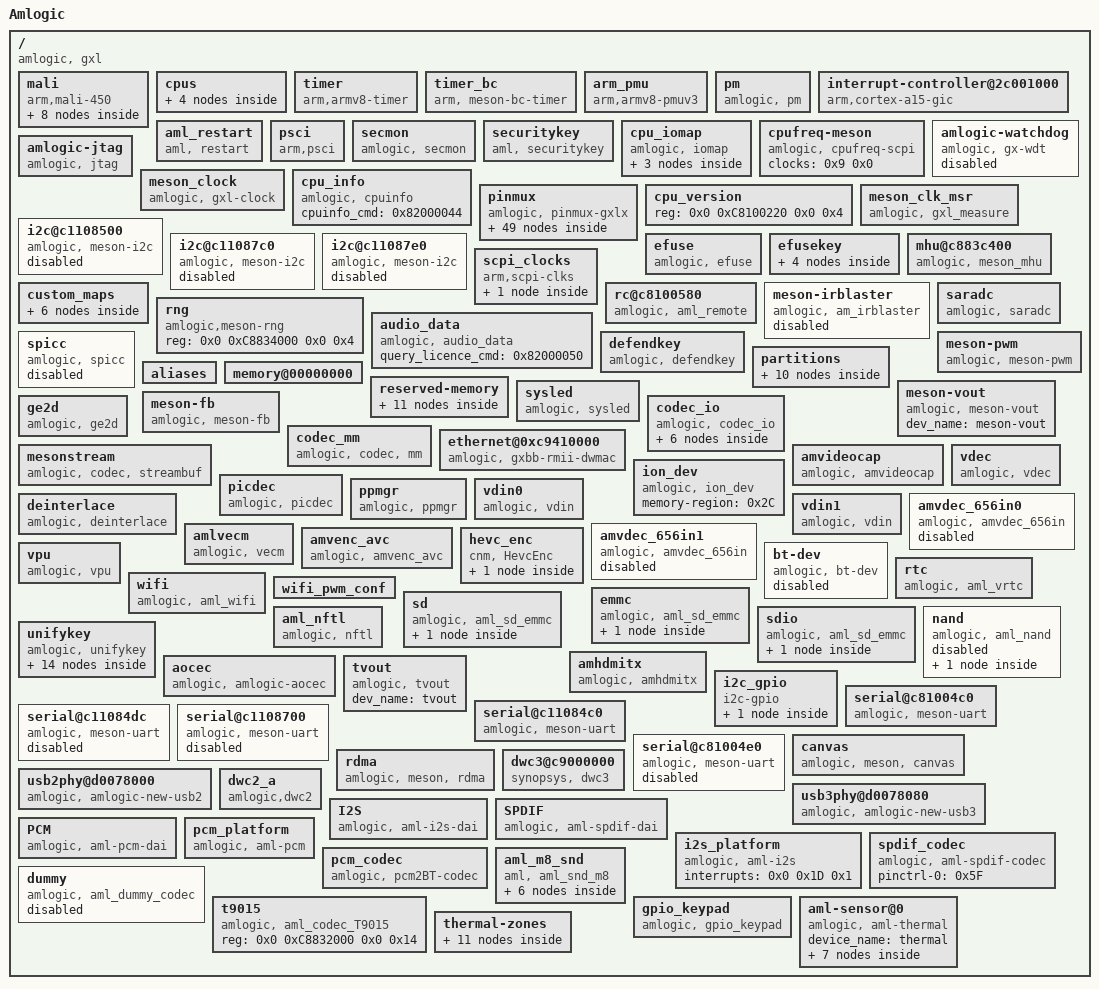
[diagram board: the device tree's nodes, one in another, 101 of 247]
/dts-v1/;
// version: 17
// last_comp_version: 16
// boot_cpuid_phys: 0x0

/ {
    model = "Amlogic";
    compatible = "amlogic, gxl";
    interrupt-parent = <0x1>;
    #address-cells = <0x2>;
    #size-cells = <0x2>;
    mali {
        #cooling-cells = <0x2>;
        compatible = "arm,mali-450";
        interrupt-parent = <0x1>;
        reg = <0x0 0xD00C0000 0x0 0x40000 0x0 0xC1104440 0x0 0x1000 0x0 0xC8100000 0x0 0x1000 0x0 0xC883C000 0x0 0x1000 0x0 0xC1104440 0x0 0x1000>;
        interrupts = <0x0 0xA0 0x4 0x0 0xA1 0x4 0x0 0xA2 0x4 0x0 0xA3 0x4 0x0 0xA4 0x4 0x0 0xA5 0x4 0x0 0xA6 0x4 0x0 0xA7 0x4>;
        interrupt-names = "IRQGP", "IRQGPMMU", "IRQPP", "IRQPMU", "IRQPP0", "IRQPPMMU0", "IRQPP1", "IRQPPMMU1";
        pmu_domain_config = <0x1 0x2 0x4 0x0 0x0 0x0 0x0 0x0 0x0 0x1 0x2 0x0>;
        pmu_switch_delay = <0xFFFF>;
        num_of_pp = <0x2>;
        def_clock = <0x3>;
        sc_mpp = <0x2>;
        tbl = <0x2 0x3 0x4 0x5 0x6 0x6>;
        clocks = <0x7 0x8 0x7 0x9 0x7 0x11 0x7 0x12 0x7 0x1E 0x7 0x15 0x7 0x13 0x7 0x14>;
        clock-names = "fclk_div3", "fclk_div4", "fclk_div5", "fclk_div7", "gp0_pll", "clk_mali", "clk_mali_0", "clk_mali_1";
        control_interval = <0xC8>;
        linux,phandle = <0x74>;
        phandle = <0x74>;
        clk125_cfg {
            clk_freq = <0x7735940>;
            clk_parent = "fclk_div4";
            clkp_freq = <0x1DCD6500>;
            voltage = <0x47E>;
            keep_count = <0x5>;
            threshold = <0x1E 0xFA>;
            linux,phandle = <0x2>;
            phandle = <0x2>;
        };
        clk250_cfg {
            clk_freq = <0xEE6B280>;
            clk_parent = "fclk_div4";
            clkp_freq = <0x1DCD6500>;
            voltage = <0x47E>;
            keep_count = <0x5>;
            threshold = <0x73 0xFA>;
        };
        clk285_cfg {
            clk_freq = <0x10FCC140>;
            clk_parent = "fclk_div7";
            clkp_freq = <0x10FCC140>;
            voltage = <0x47E>;
            keep_count = <0x5>;
            threshold = <0x64 0xFA>;
            linux,phandle = <0x3>;
            phandle = <0x3>;
        };
        clk400_cfg {
            clk_freq = <0x17D78400>;
            clk_parent = "fclk_div5";
            clkp_freq = <0x17D78400>;
            voltage = <0x47E>;
            keep_count = <0x3>;
            threshold = <0xA8 0xFA>;
            linux,phandle = <0x4>;
            phandle = <0x4>;
        };
        clk500_cfg {
            clk_freq = <0x1DCD6500>;
            clk_parent = "fclk_div4";
            clkp_freq = <0x1DCD6500>;
            voltage = <0x47E>;
            keep_count = <0x2>;
            threshold = <0xBE 0xFA>;
            linux,phandle = <0x5>;
            phandle = <0x5>;
        };
        clk666_cfg {
            clk_freq = <0x27B25A80>;
            clk_parent = "fclk_div3";
            clkp_freq = <0x27B25A80>;
            voltage = <0x47E>;
            keep_count = <0x1>;
            threshold = <0xB1 0xFA>;
            linux,phandle = <0x6>;
            phandle = <0x6>;
        };
        clk750_cfg {
            clk_freq = <0x2C588A00>;
            clk_parent = "gp0_pll";
            clkp_freq = <0x2C588A00>;
            voltage = <0x47E>;
            keep_count = <0x1>;
            threshold = <0xD5 0xFF>;
        };
        clk800_cfg {
            clk_freq = <0x2F34F600>;
            clk_parent = "gp0_pll";
            clkp_freq = <0x2F34F600>;
            voltage = <0x47E>;
            keep_count = <0x1>;
            threshold = <0xE6 0xFF>;
        };
    };
    cpus {
        #address-cells = <0x2>;
        #size-cells = <0x0>;
        #cooling-cells = <0x2>;
        linux,phandle = <0x72>;
        phandle = <0x72>;
        cpu@0 {
            device_type = "cpu";
            compatible = "arm,cortex-a53", "arm,armv8";
            reg = <0x0 0x0>;
            enable-method = "psci";
        };
        cpu@1 {
            device_type = "cpu";
            compatible = "arm,cortex-a53", "arm,armv8";
            reg = <0x0 0x1>;
            enable-method = "psci";
        };
        cpu@2 {
            device_type = "cpu";
            compatible = "arm,cortex-a53", "arm,armv8";
            reg = <0x0 0x2>;
            enable-method = "psci";
        };
        cpu@3 {
            device_type = "cpu";
            compatible = "arm,cortex-a53", "arm,armv8";
            reg = <0x0 0x3>;
            enable-method = "psci";
        };
    };
    timer {
        compatible = "arm,armv8-timer";
        interrupts = <0x1 0xD 0xFF01 0x1 0xE 0xFF01 0x1 0xB 0xFF01 0x1 0xA 0xFF01>;
    };
    timer_bc {
        compatible = "arm, meson-bc-timer";
        reg = <0x0 0xC1109990 0x0 0x4 0x0 0xC1109994 0x0 0x4>;
        timer_name = "Meson TimerF";
        clockevent-rating = <0x12C>;
        clockevent-shift = <0x14>;
        clockevent-features = <0x23>;
        interrupts = <0x0 0x3C 0x1>;
        bit_enable = <0x10>;
        bit_mode = <0xC>;
        bit_resolution = <0x0>;
    };
    arm_pmu {
        compatible = "arm,armv8-pmuv3";
        interrupts = <0x0 0x89 0x4 0x0 0x8A 0x4 0x0 0x99 0x4 0x0 0x9A 0x4>;
    };
    pm {
        compatible = "amlogic, pm";
        device_name = "aml_pm";
        gxbaby-suspend;
        reg = <0x0 0xC81000A8 0x0 0x4 0x0 0xC810023C 0x0 0x4>;
    };
    interrupt-controller@2c001000 {
        compatible = "arm,cortex-a15-gic", "arm,cortex-a9-gic";
        #interrupt-cells = <0x3>;
        #address-cells = <0x0>;
        interrupt-controller;
        reg = <0x0 0xC4301000 0x0 0x1000 0x0 0xC4302000 0x0 0x100>;
        interrupts = <0x1 0x9 0xF04>;
        linux,phandle = <0x1>;
        phandle = <0x1>;
    };
    aml_restart {
        compatible = "aml, restart";
        sys_reset = <0x84000009>;
        sys_poweroff = <0x84000008>;
    };
    psci {
        compatible = "arm,psci";
        method = "smc";
        cpu_suspend = <0xC4000001>;
        cpu_off = <0x84000002>;
        cpu_on = <0xC4000003>;
        migrate = <0xC4000005>;
    };
    secmon {
        compatible = "amlogic, secmon";
        memory-region = <0x8>;
        in_base_func = <0x82000020>;
        out_base_func = <0x82000021>;
    };
    securitykey {
        compatible = "aml, securitykey";
        storage_query = <0x82000060>;
        storage_read = <0x82000061>;
        storage_write = <0x82000062>;
        storage_tell = <0x82000063>;
        storage_verify = <0x82000064>;
        storage_status = <0x82000065>;
        storage_list = <0x82000067>;
        storage_remove = <0x82000068>;
        storage_in_func = <0x82000023>;
        storage_out_func = <0x82000024>;
        storage_block_func = <0x82000025>;
        storage_size_func = <0x82000027>;
    };
    cpu_iomap {
        compatible = "amlogic, iomap";
        #address-cells = <0x2>;
        #size-cells = <0x2>;
        ranges;
        io_cbus_base {
            reg = <0x0 0xC1100000 0x0 0x100000>;
        };
        io_apb_base {
            reg = <0x0 0xD0000000 0x0 0x200000>;
        };
        io_aobus_base {
            reg = <0x0 0xC8100000 0x0 0x100000>;
        };
    };
    cpufreq-meson {
        compatible = "amlogic, cpufreq-scpi";
        status = "okay";
        clocks = <0x9 0x0>;
        clock-names = "cpu_clk";
    };
    amlogic-watchdog {
        compatible = "amlogic, gx-wdt";
        status = "disable";
        default_timeout = <0xA>;
        reset_watchdog_method = <0x1>;
        reset_watchdog_time = <0x2>;
        shutdown_timeout = <0xA>;
        firmware_timeout = <0x6>;
        suspend_timeout = <0x6>;
        reg = <0x0 0xC11098D0 0x0 0x10>;
        clocks = <0x7 0x2>;
    };
    amlogic-jtag {
        compatible = "amlogic, jtag";
        status = "okay";
        pinctrl-names = "jtag_apao_pins", "jtag_apee_pins";
        pinctrl-0 = <0xA>;
        pinctrl-1 = <0xB>;
    };
    meson_clock {
        compatible = "amlogic, gxl-clock";
        reg = <0x0 0xC883C000 0x0 0x1000 0x0 0xC8100000 0x0 0x1000>;
        #clock-cells = <0x1>;
        #reset-cells = <0x1>;
        sys_max = <0x5B8D8000>;
        linux,phandle = <0x7>;
        phandle = <0x7>;
    };
    cpu_info {
        compatible = "amlogic, cpuinfo";
        cpuinfo_cmd = <0x82000044>;
    };
    pinmux {
        compatible = "amlogic, pinmux-gxlx";
        dev_name = "pinmux";
        #pinmux-cells = <0x2>;
        #address-cells = <0x2>;
        #size-cells = <0x2>;
        reg = <0x0 0xC1109880 0x0 0x10>;
        ranges;
        banks@c11080b0 {
            reg = <0x0 0xC88344B0 0x0 0x28 0x0 0xC88344E8 0x0 0x14 0x0 0xC8834520 0x0 0x14 0x0 0xC8834430 0x0 0x40>;
            reg-names = "mux", "pull", "pull-enable", "gpio";
            gpio-controller;
            #gpio-cells = <0x2>;
            linux,phandle = <0x28>;
            phandle = <0x28>;
        };
        ao-bank@c1108030 {
            reg = <0x0 0xC8100014 0x0 0x8 0x0 0xC810002C 0x0 0x4 0x0 0xC8100024 0x0 0x8>;
            reg-names = "mux", "pull", "gpio";
            gpio-controller;
            #gpio-cells = <0x2>;
            linux,phandle = <0x6F>;
            phandle = <0x6F>;
        };
        internal_eth_pins {
            amlogic,setmask = <0x4 0x3000000>;
            amlogic,clrmask = <0x3 0x300000>;
            amlogic,pins = "GPIOZ_14", "GPIOZ_15";
        };
        jtag_apao_pin {
            amlogic,clrmask = <0x6 0x7FE0000>;
            amlogic,pins = "GPIOH_6", "GPIOH_7", "GPIOH_8", "GPIOH_9";
            linux,phandle = <0xA>;
            phandle = <0xA>;
        };
        jtag_apee_pin {
            amlogic,clrmask = <0x6 0x3C>;
            amlogic,pins = "CARD_0", "CARD_1", "CARD_2", "CARD_3";
            linux,phandle = <0xB>;
            phandle = <0xB>;
        };
        remote_pin {
            amlogic,setmask = <0x10 0x1>;
            amlogic,clrmask = <0x10 0x200000>;
            amlogic,pins = "GPIOAO_7";
            linux,phandle = <0x15>;
            phandle = <0x15>;
        };
        irblaster_pin {
            amlogic,setmask = <0x10 0x200000>;
            amlogic,clrmask = <0x10 0x1>;
            amlogic,pins = "GPIOAO_7";
            linux,phandle = <0x17>;
            phandle = <0x17>;
        };
        ao_uart {
            amlogic,setmask = <0x10 0x1800>;
            amlogic,pins = "GPIOAO_0", "GPIOAO_1";
        };
        ao_b_uart {
            amlogic,setmask = <0x10 0x1800000>;
            amlogic,pins = "GPIOAO_4", "GPIOAO_5";
            linux,phandle = <0x5B>;
            phandle = <0x5B>;
        };
        a_uart {
            amlogic,setmask = <0x5 0xF0000>;
            amlogic,clrmask = <0x5 0x3C0>;
            amlogic,pins = "GPIOX_12", "GPIOX_13", "GPIOX_14", "GPIOX_15";
            linux,phandle = <0x58>;
            phandle = <0x58>;
        };
        b_uart {
            amlogic,setmask = <0x2 0x18000>;
            amlogic,pins = "GPIODV_24", "GPIODV_25";
            linux,phandle = <0x59>;
            phandle = <0x59>;
        };
        c_uart {
            amlogic,setmask = <0x5 0x3000>;
            amlogic,pins = "GPIOX_8", "GPIOX_9";
            linux,phandle = <0x5A>;
            phandle = <0x5A>;
        };
        wifi_32k_pins {
            amlogic,setmask = <0x5 0x8000>;
            amlogic,pins = "GPIOX_16";
            linux,phandle = <0x31>;
            phandle = <0x31>;
        };
        sd_clk_cmd_pins {
            amlogic,setmask = <0x6 0xC 0x10 0x1800>;
            amlogic,pins = "CARD_2", "CARD_3";
            amlogic,enable-output = <0x1>;
            amlogic,pullup = <0x1>;
            amlogic,pullupen = <0x1>;
            linux,phandle = <0x36>;
            phandle = <0x36>;
        };
        sd_all_pins {
            amlogic,setmask = <0x6 0x3F 0x10 0x1800>;
            amlogic,clrmask = <0x6 0xFC0>;
            amlogic,pins = "CARD_0", "CARD_1", "CARD_2", "CARD_3", "CARD_4", "CARD_5";
            amlogic,enable-output = <0x1>;
            amlogic,pullup = <0x1>;
            amlogic,pullupen = <0x1>;
            linux,phandle = <0x37>;
            phandle = <0x37>;
        };
        sd_clear_all_pin {
            amlogic,setmask = <0x10 0x1800>;
            amlogic,clrmask = <0x6 0x3F 0x6 0xFC0>;
            amlogic,pins = "GPIOAO_0", "GPIOAO_1";
            amlogic,enable-output = <0x1>;
            amlogic,pullup = <0x1>;
            amlogic,pullupen = <0x1>;
            linux,phandle = <0x3F>;
            phandle = <0x3F>;
        };
        sd_1bit_pins {
            amlogic,setmask = <0x6 0x1C 0x10 0x1800>;
            amlogic,clrmask = <0x6 0xCC3>;
            amlogic,pins = "CARD_1", "CARD_2", "CARD_3";
            amlogic,enable-output = <0x1>;
            amlogic,pullup = <0x1>;
            amlogic,pullupen = <0x1>;
            linux,phandle = <0x38>;
            phandle = <0x38>;
        };
        sd_clk_cmd_uart_pins {
            amlogic,setmask = <0x6 0x30C>;
            amlogic,clrmask = <0x6 0xCC3 0x10 0x1800>;
            amlogic,pins = "CARD_2", "CARD_3";
            amlogic,enable-output = <0x1>;
            amlogic,pullup = <0x1>;
            amlogic,pullupen = <0x1>;
            linux,phandle = <0x39>;
            phandle = <0x39>;
        };
        sd_1bit_uart_pins {
            amlogic,setmask = <0x6 0x31C>;
            amlogic,clrmask = <0x6 0xCC3 0x10 0x1800>;
            amlogic,pins = "CARD_1", "CARD_2", "CARD_3";
            amlogic,enable-output = <0x1>;
            amlogic,pullup = <0x1>;
            amlogic,pullupen = <0x1>;
            linux,phandle = <0x3A>;
            phandle = <0x3A>;
        };
        sd_to_ao_uart_pins {
            amlogic,setmask = <0x10 0x1800>;
            amlogic,clrmask = <0x6 0x300>;
            amlogic,pins = "GPIOAO_0", "GPIOAO_1";
            amlogic,enable-output = <0x1>;
            amlogic,pullup = <0x1>;
            amlogic,pullupen = <0x1>;
            linux,phandle = <0x3B>;
            phandle = <0x3B>;
        };
        ao_to_sd_uart_pins {
            amlogic,setmask = <0x6 0x300>;
            amlogic,clrmask = <0x10 0x1800 0x6 0xCC3>;
            amlogic,pins = "CARD_4", "CARD_5";
            amlogic,enable-output = <0x1>;
            amlogic,pullup = <0x1>;
            amlogic,pullupen = <0x1>;
            linux,phandle = <0x3C>;
            phandle = <0x3C>;
        };
        ao_to_sd_jtag_pins {
            amlogic,setmask = <0x6 0x300>;
            amlogic,clrmask = <0x6 0xCFF 0x10 0x1800>;
            amlogic,pins = "CARD_4", "CARD_5";
            amlogic,enable-output = <0x1>;
            amlogic,pullup = <0x1>;
            amlogic,pullupen = <0x1>;
            linux,phandle = <0x3D>;
            phandle = <0x3D>;
        };
        sd_to_ao_jtag_pins {
            amlogic,setmask = <0x10 0x1800>;
            amlogic,clrmask = <0x6 0xFC0>;
            amlogic,pins = "GPIOAO_0", "GPIOAO_1";
            amlogic,enable-output = <0x1>;
            amlogic,pullup = <0x1>;
            amlogic,pullupen = <0x1>;
            linux,phandle = <0x3E>;
            phandle = <0x3E>;
        };
        emmc_conf_pull_up {
            amlogic,pins = "BOOT_0", "BOOT_1", "BOOT_2", "BOOT_3", "BOOT_4", "BOOT_5", "BOOT_6", "BOOT_7", "BOOT_8", "BOOT_10";
            amlogic,pullup = <0x1>;
            amlogic,pullupen = <0x1>;
            linux,phandle = <0x33>;
            phandle = <0x33>;
        };
        emmc_conf_pull_done {
            amlogic,pins = "BOOT_15";
            amlogic,pullup = <0x0>;
            amlogic,pullupen = <0x1>;
            linux,phandle = <0x34>;
            phandle = <0x34>;
        };
        emmc_clk_cmd_pins {
            amlogic,setmask = <0x7 0x60000000>;
            amlogic,clrmask = <0x7 0xE0>;
            amlogic,pins = "BOOT_8", "BOOT_10";
            amlogic,enable-output = <0x1>;
            amlogic,pullup = <0x1>;
            amlogic,pullupen = <0x1>;
            linux,phandle = <0x32>;
            phandle = <0x32>;
        };
        emmc_all_pins {
            amlogic,setmask = <0x7 0xF0000000>;
            amlogic,clrmask = <0x7 0xE0>;
            amlogic,pins = "BOOT_0", "BOOT_1", "BOOT_2", "BOOT_3", "BOOT_4", "BOOT_5", "BOOT_6", "BOOT_7", "BOOT_8", "BOOT_10", "BOOT_15";
            amlogic,enable-output = <0x1>;
            linux,phandle = <0x35>;
            phandle = <0x35>;
        };
        sdio_clk_cmd_pins {
            amlogic,setmask = <0x5 0xC000000>;
            amlogic,pins = "GPIOX_4", "GPIOX_5";
            amlogic,enable-output = <0x1>;
            amlogic,pullup = <0x1>;
            amlogic,pullupen = <0x1>;
            linux,phandle = <0x40>;
            phandle = <0x40>;
        };
        sdio_all_pins {
            amlogic,setmask = <0x5 0xFC000000>;
            amlogic,pins = "GPIOX_0", "GPIOX_1", "GPIOX_2", "GPIOX_3", "GPIOX_4", "GPIOX_5";
            amlogic,enable-output = <0x1>;
            amlogic,pullup = <0x1>;
            amlogic,pullupen = <0x1>;
            linux,phandle = <0x41>;
            phandle = <0x41>;
        };
        conf_nand_pulldown {
            amlogic,pins = "BOOT_0", "BOOT_1", "BOOT_2", "BOOT_3", "BOOT_4", "BOOT_5", "BOOT_6", "BOOT_7", "BOOT_15";
            amlogic,pullup = <0x0>;
            amlogic,pullupen = <0x1>;
            linux,phandle = <0x42>;
            phandle = <0x42>;
        };
        conf_nand_pullup {
            amlogic,pins = "BOOT_8", "BOOT_10";
            amlogic,pullup = <0x1>;
            amlogic,pullupen = <0x1>;
            linux,phandle = <0x43>;
            phandle = <0x43>;
        };
        all_nand_pins {
            amlogic,setmask = <0x7 0x800000FF>;
            amlogic,clrmask = <0x7 0x70FFBC00>;
            amlogic,pins = "BOOT_0", "BOOT_1", "BOOT_2", "BOOT_3", "BOOT_4", "BOOT_5", "BOOT_6", "BOOT_7", "BOOT_8", "BOOT_9", "BOOT_10", "BOOT_11", "BOOT_12", "BOOT_13", "BOOT_14", "BOOT_15";
            amlogic,enable-output = <0x1>;
            linux,phandle = <0x44>;
            phandle = <0x44>;
        };
        nand_cs {
            amlogic,setmask = <0x7 0xC0>;
            amlogic,clrmask = <0x7 0x40040000>;
            amlogic,pins = "BOOT_8", "BOOT_9";
            linux,phandle = <0x45>;
            phandle = <0x45>;
        };
        hdmitx_hpd {
            amlogic,setmask = <0x6 0x80000000>;
            amlogic,pins = "GPIOH_0";
            linux,phandle = <0x55>;
            phandle = <0x55>;
        };
        hdmitx_ddc {
            amlogic,setmask = <0x6 0x30000000>;
            amlogic,pins = "GPIOH_1", "GPIOH_2";
            linux,phandle = <0x56>;
            phandle = <0x56>;
        };
        hdmitx_aocec {
            amlogic,setmask = <0x10 0x8000>;
            amlogic,clrmask = <0x10 0x24000 0x11 0x1>;
            amlogic,pins = "GPIOAO_8";
            linux,phandle = <0x57>;
            phandle = <0x57>;
        };
        hdmitx_eecec {
            amlogic,setmask = <0x10 0x4000>;
            amlogic,clrmask = <0x10 0x28000 0x11 0x1>;
            amlogic,pins = "GPIOAO_8";
        };
        a_i2c {
            amlogic,setmask = <0x1 0xC000>;
            amlogic,clrmask = <0x3 0x18 0x2 0x18000 0x2 0xC0 0x1 0x600000>;
            amlogic,pins = "GPIODV_24", "GPIODV_25";
            linux,phandle = <0xC>;
            phandle = <0xC>;
        };
        b_i2c {
            amlogic,setmask = <0x1 0x3000>;
            amlogic,clrmask = <0x2 0x6000 0x1 0x1C0000>;
            amlogic,pins = "GPIODV_26", "GPIODV_27";
            linux,phandle = <0xD>;
            phandle = <0xD>;
        };
        c_i2c {
            amlogic,setmask = <0x1 0xC00>;
            amlogic,clrmask = <0x2 0x1800 0x1 0x200 0x2 0x20>;
            amlogic,pins = "GPIODV_28", "GPIODV_29";
            linux,phandle = <0xE>;
            phandle = <0xE>;
        };
        spicc_pins_z11z12z13 {
            amlogic,setmask = <0x4 0x1C>;
            amlogic,clrmask = <0x3 0x800 0x4 0x1C00>;
            amlogic,pins = "GPIOZ_11", "GPIOZ_12", "GPIOZ_13";
        };
        spicc_pulldown_z11z12z13 {
            amlogic,pins = "GPIOZ_11", "GPIOZ_12", "GPIOZ_13";
            amlogic,pullup = <0x0>;
            amlogic,pullupen = <0x1>;
        };
        spicc_pullup_z11z12z13 {
            amlogic,pins = "GPIOZ_11", "GPIOZ_12", "GPIOZ_13";
            amlogic,pullup = <0x1>;
            amlogic,pullupen = <0x1>;
        };
        spicc_pins_x8x9x11 {
            amlogic,setmask = <0x5 0xD>;
            amlogic,clrmask = <0x5 0xD03430 0x6 0xD>;
            amlogic,pins = "GPIOX_8", "GPIOX_9", "GPIOX_11";
        };
        spicc_pulldown_x8x9x11 {
            amlogic,pins = "GPIOX_8", "GPIOX_9", "GPIOX_11";
            amlogic,pullup = <0x0>;
            amlogic,pullupen = <0x1>;
        };
        spicc_pullup_x8x9x11 {
            amlogic,pins = "GPIOX_8", "GPIOX_9", "GPIOX_11";
            amlogic,pullup = <0x1>;
            amlogic,pullupen = <0x1>;
        };
        audio_pin {
            amlogic,setmask = <0x6 0x7800000>;
            amlogic,clrmask = <0x6 0x7E0000>;
            amlogic,pins = "GPIOH_6", "GPIOH_7", "GPIOH_8", "GPIOH_9";
            linux,phandle = <0x60>;
            phandle = <0x60>;
        };
        audio_pin1 {
            amlogic,setmask = <0x6 0x10000000>;
            amlogic,clrmask = <0x6 0x8000000>;
            amlogic,pins = "GPIOH_4";
            linux,phandle = <0x5F>;
            phandle = <0x5F>;
        };
        audio_btpcm_pins {
            amlogic,setmask = <0x5 0xF00000>;
            amlogic,clrmask = <0x5 0x3C33>;
            amlogic,pins = "GPIOX_8", "GPIOX_9", "GPIOX_10", "GPIOX_11";
            linux,phandle = <0x5E>;
            phandle = <0x5E>;
        };
    };
    cpu_version {
        reg = <0x0 0xC8100220 0x0 0x4>;
    };
    meson_clk_msr {
        compatible = "amlogic, gxl_measure";
        reg = <0x0 0xC110875C 0x0 0x4 0x0 0xC1108764 0x0 0x4>;
    };
    i2c@c1108500 {
        compatible = "amlogic, meson-i2c";
        dev_name = "i2c-A";
        status = "disabled";
        reg = <0x0 0xC1108500 0x0 0x20>;
        device_id = <0x1>;
        pinctrl-names = "default";
        pinctrl-0 = <0xC>;
        #address-cells = <0x1>;
        #size-cells = <0x0>;
        use_pio = <0x0>;
        master_i2c_speed = <0x493E0>;
        clocks = <0x7 0xA>;
        clock-names = "clk_i2c";
        resets = <0x7 0x9>;
    };
    i2c@c11087c0 {
        compatible = "amlogic, meson-i2c";
        dev_name = "i2c-B";
        status = "disabled";
        reg = <0x0 0xC11087C0 0x0 0x20>;
        device_id = <0x2>;
        pinctrl-names = "default";
        pinctrl-0 = <0xD>;
        #address-cells = <0x1>;
        #size-cells = <0x0>;
        use_pio = <0x0>;
        master_i2c_speed = <0x493E0>;
        clocks = <0x7 0xA>;
        clock-names = "clk_i2c";
        resets = <0x7 0x9>;
    };
    i2c@c11087e0 {
        compatible = "amlogic, meson-i2c";
        dev_name = "i2c-C";
        status = "disabled";
        reg = <0x0 0xC11087E0 0x0 0x20>;
        device_id = <0x3>;
        pinctrl-names = "default";
        pinctrl-0 = <0xE>;
        #address-cells = <0x1>;
        #size-cells = <0x0>;
        use_pio = <0x0>;
        master_i2c_speed = <0x493E0>;
        clocks = <0x7 0xA>;
        clock-names = "clk_i2c";
        resets = <0x7 0x9>;
    };
    efuse {
        compatible = "amlogic, efuse";
        read_cmd = <0x82000030>;
        write_cmd = <0x82000031>;
        get_max_cmd = <0x82000033>;
        key = <0xF>;
        resets = <0x7 0x3E>;
        reset-names = "efuse_clk";
        status = "okay";
    };
    efusekey {
        keynum = <0x4>;
        key0 = <0x10>;
        key1 = <0x11>;
        key2 = <0x12>;
        key3 = <0x13>;
        linux,phandle = <0xF>;
        phandle = <0xF>;
        key0 {
            keyname = "mac";
            offset = <0x0>;
            size = <0x6>;
            linux,phandle = <0x10>;
            phandle = <0x10>;
        };
        key1 {
            keyname = "mac_bt";
            offset = <0x6>;
            size = <0x6>;
            linux,phandle = <0x11>;
            phandle = <0x11>;
        };
        key2 {
            keyname = "mac_wifi";
            offset = <0xC>;
            size = <0x6>;
            linux,phandle = <0x12>;
            phandle = <0x12>;
        };
        key3 {
            keyname = "usid";
            offset = <0x12>;
            size = <0x10>;
            linux,phandle = <0x13>;
            phandle = <0x13>;
        };
    };
    mhu@c883c400 {
        compatible = "amlogic, meson_mhu";
        reg = <0x0 0xC883C400 0x0 0x4C 0x0 0xC8013000 0x0 0x800>;
        interrupts = <0x0 0xD1 0x8 0x0 0xD2 0x8>;
        #mbox-cells = <0x1>;
        mbox-names = "cpu_to_scp_low", "cpu_to_scp_high";
        mboxes = <0x14 0x0 0x14 0x1>;
        linux,phandle = <0x14>;
        phandle = <0x14>;
    };
    scpi_clocks {
        compatible = "arm,scpi-clks";
        scpi_clocks@0 {
            compatible = "arm,scpi-clk-indexed";
            #clock-cells = <0x1>;
            clock-indices = <0x0>;
            clock-output-names = "vcpu";
            linux,phandle = <0x9>;
            phandle = <0x9>;
        };
    };
    rc@c8100580 {
        compatible = "amlogic, aml_remote";
        dev_name = "meson-remote";
        reg = <0x0 0xC8100580 0x0 0x44 0x0 0xC8100480 0x0 0x20>;
        status = "okay";
        protocol = <0x1>;
        interrupts = <0x0 0xC4 0x1>;
        pinctrl-names = "default";
        pinctrl-0 = <0x15>;
        map = <0x16>;
        max_frame_time = <0xC8>;
    };
    meson-irblaster {
        compatible = "amlogic, am_irblaster";
        dev_name = "meson-irblaster";
        status = "disabled";
        pinctrl-names = "default";
        pinctrl-0 = <0x17>;
    };
    custom_maps {
        mapnum = <0x6>;
        map0 = <0x18>;
        map1 = <0x19>;
        map2 = <0x1A>;
        map3 = <0x1B>;
        map4 = <0x1C>;
        map5 = <0x1D>;
        linux,phandle = <0x16>;
        phandle = <0x16>;
        map_0 {
            mapname = "cyxtech-remote-a95x";
            customcode = <0xDF00>;
            release_delay = <0x50>;
            size = <0x1B>;
            keymap = <0xC000B 0x540002 0x160003 0x150004 0x500005 0x120006 0x110007 0x4C0008 0xE0009 0xD000A 0x10000E 0x1A0067 0x48006C 0x470069 0x7006A 0x60061 0x4B007A 0x4F007B 0x1C0074 0x420066 0xA009E 0x18008B 0x5D0073 0x5C0072 0x410046 0x10186 0x5F018A>;
            linux,phandle = <0x18>;
            phandle = <0x18>;
        };
        map_1 {
            mapname = "cyxtech-remote-cs918";
            customcode = <0x4040>;
            release_delay = <0x50>;
            size = <0x1D>;
            keymap = <0xB 0x10002 0x20003 0x30004 0x40005 0x50006 0x60007 0x70008 0x80009 0x9000A 0xC000E 0xB0067 0xE006C 0x100069 0x11006A 0xD0061 0x1E007A 0x1F007B 0x4D0074 0x1A0066 0x42009E 0x45008B 0x150073 0x1C0072 0x430071 0x570046 0x5B018B 0x540188 0x530189>;
            linux,phandle = <0x19>;
            phandle = <0x19>;
        };
        map_2 {
            mapname = "cyxtech-remote-8200";
            customcode = <0xFE01>;
            release_delay = <0x50>;
            size = <0x1B>;
            keymap = <0x1000B 0x4E0002 0xD0003 0xC0004 0x4A0005 0x90006 0x80007 0x460008 0x50009 0x4000A 0x42000E 0x160067 0x1A006C 0x510069 0x50006A 0x130061 0x4B007A 0x4F007B 0x400074 0x110066 0x19009E 0x8B 0x180073 0x100072 0x410046 0xF0186 0x43018A>;
            linux,phandle = <0x1A>;
            phandle = <0x1A>;
        };
        map_3 {
            mapname = "cyxtech-remote-test";
            customcode = <0xDF20>;
            release_delay = <0x50>;
            size = <0xC>;
            keymap = <0x410000 0x500000 0x420000 0x1A0000 0x1B0000 0x4F0000 0x430000 0x140000 0x4D0000 0x5A0190 0x560191 0x510192>;
            linux,phandle = <0x1B>;
            phandle = <0x1B>;
        };
        map_4 {
            mapname = "cyxtech-remote-test2";
            customcode = <0xFF00>;
            release_delay = <0x50>;
            size = <0x9>;
            keymap = <0x470190 0x460191 0x450192 0x4A0000 0x4B0000 0x490000 0x4E0000 0x4F0000 0x4D0000>;
            linux,phandle = <0x1C>;
            phandle = <0x1C>;
        };
        map_5 {
            mapname = "remote_mouse_r2a";
            customcode = <0x7F80>;
            release_delay = <0x50>;
            size = <0xC>;
            keymap = <0x810074 0x890072 0x870073 0x730066 0x83008B 0x380067 0x40006C 0x370069 0x39006A 0x130061 0x27009E 0x480184>;
            linux,phandle = <0x1D>;
            phandle = <0x1D>;
        };
    };
    rng {
        compatible = "amlogic,meson-rng";
        reg = <0x0 0xC8834000 0x0 0x4>;
    };
    audio_data {
        compatible = "amlogic, audio_data";
        query_licence_cmd = <0x82000050>;
        status = "okay";
    };
    saradc {
        compatible = "amlogic, saradc";
        status = "okay";
        interrupts = <0x0 0x9 0x1>;
        interrupt-names = "saradc_int";
        clocks = <0x7 0x2>;
        clock-names = "saradc_clk";
        resets = <0x7 0x56>;
        reg = <0x0 0xC1108680 0x0 0x30 0x0 0xC883C3D8 0x0 0x8>;
    };
    defendkey {
        compatible = "amlogic, defendkey";
        reg = <0x0 0xC8834500 0x0 0x4>;
        mem_size = <0x0 0x100000>;
        status = "okay";
    };
    spicc {
        compatible = "amlogic, spicc";
        status = "disabled";
        reg = <0x0 0xC1108D80 0x0 0x28>;
        resets = <0x7 0x8>;
        clocks = <0x7 0xA>;
        clock-names = "spicc_clk";
        interrupts = <0x0 0x51 0x1>;
        device_id = <0x0>;
    };
    meson-pwm {
        compatible = "amlogic, meson-pwm";
        status = "okay";
        #pwm-cells = <0x2>;
        pwm-outputs = <0x0 0x1 0x2 0x3 0x4 0x5 0x6 0x7 0x8 0x9 0xA 0xB 0xC 0xD 0xE 0xF>;
        reg = <0x0 0xC1108550 0x0 0x1C 0x0 0xC1108640 0x0 0x1C 0x0 0xC11086C0 0x0 0x1C 0x0 0xC8100550 0x0 0x1C>;
        clocks = <0x7 0x2 0x7 0x5 0x7 0x9 0x7 0x8>;
        clock-names = "xtal", "vid_pll_clk", "fclk_div4", "fclk_div3";
        clock-select = <0x0 0x0 0x0 0x0 0x0 0x0 0x0 0x0>;
    };
    partitions {
        parts = <0xA>;
        part-0 = <0x1E>;
        part-1 = <0x1F>;
        part-2 = <0x20>;
        part-3 = <0x21>;
        part-4 = <0x22>;
        part-5 = <0x23>;
        part-6 = <0x24>;
        part-7 = <0x25>;
        part-8 = <0x26>;
        part-9 = <0x27>;
        logo {
            pname = "logo";
            size = <0x0 0x2000000>;
            mask = <0x1>;
            linux,phandle = <0x1E>;
            phandle = <0x1E>;
        };
        recovery {
            pname = "recovery";
            size = <0x0 0x2000000>;
            mask = <0x1>;
            linux,phandle = <0x1F>;
            phandle = <0x1F>;
        };
        cri_data {
            pname = "cri_data";
            size = <0x0 0x800000>;
            mask = <0x1>;
            linux,phandle = <0x20>;
            phandle = <0x20>;
        };
        tee {
            pname = "tee";
            size = <0x0 0x800000>;
            mask = <0x1>;
            linux,phandle = <0x21>;
            phandle = <0x21>;
        };
        param {
            pname = "param";
            size = <0x0 0x2000000>;
            mask = <0x1>;
            linux,phandle = <0x22>;
            phandle = <0x22>;
        };
        misc {
            pname = "misc";
            size = <0x0 0x2000000>;
            mask = <0x1>;
            linux,phandle = <0x23>;
            phandle = <0x23>;
        };
        boot {
            pname = "boot";
            size = <0x0 0x2000000>;
            mask = <0x1>;
            linux,phandle = <0x24>;
            phandle = <0x24>;
        };
        system {
            pname = "system";
            size = <0x0 0x80000000>;
            mask = <0x1>;
            linux,phandle = <0x25>;
            phandle = <0x25>;
        };
        cache {
            pname = "cache";
            size = <0x0 0x20000000>;
            mask = <0x2>;
            linux,phandle = <0x26>;
            phandle = <0x26>;
        };
        data {
            pname = "data";
            size = <0xFFFFFFFF 0xFFFFFFFF>;
            mask = <0x4>;
            linux,phandle = <0x27>;
            phandle = <0x27>;
        };
    };
    aliases {
        serial0 = "/serial@c81004c0";
        serial1 = "/serial@c11084c0";
        serial2 = "/serial@c11084dc";
        serial3 = "/serial@c1108700";
        serial4 = "/serial@c81004e0";
    };
    memory@00000000 {
        device_type = "memory";
        linux,usable-memory = <0x0 0x100000 0x0 0x3FF00000>;
    };
    reserved-memory {
        #address-cells = <0x2>;
        #size-cells = <0x2>;
        ranges;
        linux,secmon {
            compatible = "amlogic, aml_secmon_memory";
            reg = <0x0 0x5000000 0x0 0x300000>;
            no-map;
            linux,phandle = <0x8>;
            phandle = <0x8>;
        };
        linux,secos {
            status = "disable";
            compatible = "amlogic, aml_secos_memory";
            reg = <0x0 0x5300000 0x0 0x2000000>;
            no-map;
        };
        aml_pstore {
            compatible = "amlogic, pstore";
            reg = <0x0 0x7300000 0x0 0x100000>;
            no-map;
        };
        linux,meson-fb {
            compatible = "amlogic, fb-memory";
            reg = <0x0 0x3F000000 0x0 0x1000000>;
            no-map;
            linux,phandle = <0x29>;
            phandle = <0x29>;
        };
        linux,di_cma {
            compatible = "shared-dma-pool";
            reusable;
            size = <0x0 0x2400000>;
            alignment = <0x0 0x400000>;
            linux,phandle = <0x2F>;
            phandle = <0x2F>;
        };
        linux,ion-dev {
            compatible = "amlogic, idev-mem";
            size = <0x0 0x2000000>;
            linux,phandle = <0x2C>;
            phandle = <0x2C>;
        };
        linux,vdin1_cma {
            compatible = "shared-dma-pool";
            reusable;
            size = <0x0 0x1000000>;
            alignment = <0x0 0x400000>;
            linux,phandle = <0x30>;
            phandle = <0x30>;
        };
        linux,ppmgr {
            compatible = "amlogic, ppmgr_memory";
            size = <0x0 0x0>;
            multi-use;
            linux,phandle = <0x2E>;
            phandle = <0x2E>;
        };
        linux,codec_mm_cma {
            compatible = "shared-dma-pool";
            reusable;
            size = <0x0 0xBC00000>;
            alignment = <0x0 0x400000>;
            linux,contiguous-region;
            linux,phandle = <0x2A>;
            phandle = <0x2A>;
        };
        linux,picdec {
            compatible = "shared-dma-pool";
            reusable;
            size = <0x0 0x0>;
            alignment = <0x0 0x0>;
            linux,contiguous-region;
            linux,phandle = <0x2D>;
            phandle = <0x2D>;
        };
        linux,codec_mm_reserved {
            compatible = "amlogic, codec-mm-reserved";
            size = <0x0 0x4100000>;
            alignment = <0x0 0x100000>;
            linux,phandle = <0x2B>;
            phandle = <0x2B>;
        };
    };
    sysled {
        compatible = "amlogic, sysled";
        dev_name = "sysled";
        status = "okay";
        led_gpio = <0x28 0x4C 0x0>;
        led_active_low = <0x1>;
    };
    meson-vout {
        compatible = "amlogic, meson-vout";
        dev_name = "meson-vout";
        status = "okay";
    };
    meson-fb {
        compatible = "amlogic, meson-fb";
        memory-region = <0x29>;
        dev_name = "meson-fb";
        status = "okay";
        interrupts = <0x0 0x3 0x1 0x0 0x59 0x1>;
        interrupt-names = "viu-vsync", "rdma";
        mem_size = <0xB00000 0x100000>;
        display_mode_default = "720p60hz";
        scale_mode = <0x1>;
        display_size_default = <0x500 0x2D0 0x500 0x870 0x20>;
        pxp_mode = <0x1>;
        logo_addr = "0x3f000000";
    };
    ge2d {
        compatible = "amlogic, ge2d";
        dev_name = "ge2d";
        status = "okay";
        interrupts = <0x0 0x96 0x1>;
        interrupt-names = "ge2d";
        clocks = <0x7 0x17 0x7 0x19>;
        clock-names = "clk_vapb_0", "clk_ge2d";
        resets = <0x7 0x34>;
        reset-names = "ge2d";
    };
    codec_io {
        compatible = "amlogic, codec_io";
        #address-cells = <0x2>;
        #size-cells = <0x2>;
        ranges;
        io_cbus_base {
            reg = <0x0 0xC1100000 0x0 0x100000>;
        };
        io_dos_base {
            reg = <0x0 0xC8820000 0x0 0x10000>;
        };
        io_hiubus_base {
            reg = <0x0 0xC883C000 0x0 0x2000>;
        };
        io_aobus_base {
            reg = <0x0 0xC8100000 0x0 0x100000>;
        };
        io_vcbus_base {
            reg = <0x0 0xD0100000 0x0 0x40000>;
        };
        io_dmc_base {
            reg = <0x0 0xC8838000 0x0 0x400>;
        };
    };
    codec_mm {
        compatible = "amlogic, codec, mm";
        memory-region = <0x2A 0x2B>;
        dev_name = "codec_mm";
        status = "okay";
    };
    ethernet@0xc9410000 {
        compatible = "amlogic, gxbb-rmii-dwmac";
        reg = <0x0 0xC9410000 0x0 0x10000 0x0 0xC8834540 0x0 0x8 0x0 0xC8834558 0x0 0xC>;
        interrupts = <0x0 0x8 0x1 0x0 0x9 0x1>;
        phy-mode = "rmii";
        pinctrl-names = "internal_eth_pins";
        mc_val = <0x1800>;
        resets = <0x7 0x23>;
        reset-names = "ethpower";
        interrupt-names = "macirq", "phyirq";
        clocks = <0x7 0xA>;
        clock-names = "ethclk81";
        internal_phy = <0x1>;
        wol = <0x0>;
    };
    mesonstream {
        compatible = "amlogic, codec, streambuf";
        dev_name = "mesonstream";
        status = "okay";
        resets = <0x7 0x39 0x7 0x59 0x7 0x24 0x7 0x1>;
        reset-names = "parser_top", "vpu_intr", "demux", "vdec";
    };
    amvideocap {
        compatible = "amlogic, amvideocap";
        dev_name = "amvideocap.0";
        status = "okay";
        max_size = <0x8>;
    };
    ion_dev {
        compatible = "amlogic, ion_dev";
        memory-region = <0x2C>;
    };
    vdec {
        compatible = "amlogic, vdec";
        dev_name = "vdec.0";
        status = "okay";
        interrupts = <0x0 0x3 0x1 0x0 0x17 0x1 0x0 0x20 0x1 0x0 0x2B 0x1 0x0 0x2C 0x1 0x0 0x2D 0x1>;
        interrupt-names = "vsync", "demux", "parser", "mailbox_0", "mailbox_1", "mailbox_2";
    };
    picdec {
        compatible = "amlogic, picdec";
        memory-region = <0x2D>;
        dev_name = "picdec";
        status = "okay";
    };
    ppmgr {
        compatible = "amlogic, ppmgr";
        memory-region = <0x2E>;
        dev_name = "ppmgr";
        status = "okay";
    };
    deinterlace {
        compatible = "amlogic, deinterlace";
        status = "okay";
        flag_cma = <0x2>;
        memory-region = <0x2F>;
        interrupts = <0x0 0x2E 0x1 0x0 0x6 0x1>;
        interrupt-names = "de_irq", "timerc";
        buffer-size = <0x3E2C40>;
        nr10bit-surpport = <0x1>;
        hw-version = <0x2>;
    };
    vdin0 {
        compatible = "amlogic, vdin";
        dev_name = "vdin0";
        status = "okay";
        reserve-iomap = "true";
        flag_cma = <0x1>;
        cma_size = <0x18>;
        interrupts = <0x0 0x53 0x1>;
        rdma-irq = <0x2>;
        clocks = <0x7 0x11 0x7 0x29>;
        clock-names = "fclk_div5", "cts_vdin_meas_clk";
        vdin_id = <0x0>;
        tv_bit_mode = <0x15>;
    };
    vdin1 {
        compatible = "amlogic, vdin";
        memory-region = <0x30>;
        dev_name = "vdin1";
        status = "okay";
        reserve-iomap = "true";
        flag_cma = <0x0>;
        interrupts = <0x0 0x55 0x1>;
        rdma-irq = <0x4>;
        clocks = <0x7 0x11 0x7 0x29>;
        clock-names = "fclk_div5", "cts_vdin_meas_clk";
        vdin_id = <0x1>;
        tv_bit_mode = <0x1>;
    };
    amvdec_656in0 {
        compatible = "amlogic, amvdec_656in";
        dev_name = "amvdec_656in0";
        status = "disabled";
        reg = <0x0 0xD0048000 0x0 0x7C>;
        clocks = <0x7 0x7 0x7 0x26>;
        clock-names = "fclk_div2", "cts_bt656_clk0";
        bt656_id = <0x0>;
    };
    amvdec_656in1 {
        compatible = "amlogic, amvdec_656in";
        dev_name = "amvdec_656in1";
        status = "disabled";
        reg = <0x0 0xD0050000 0x0 0x7C>;
        clocks = <0x7 0x7 0x7 0x27>;
        clock-names = "fclk_div2", "cts_bt656_clk1";
        bt656_id = <0x1>;
    };
    amlvecm {
        compatible = "amlogic, vecm";
        dev_name = "aml_vecm";
        status = "okay";
        gamma_en = <0x0>;
        wb_en = <0x0>;
        cm_en = <0x0>;
        wb_sel = <0x0>;
    };
    amvenc_avc {
        compatible = "amlogic, amvenc_avc";
        dev_name = "amvenc_avc";
        status = "okay";
        interrupts = <0x0 0x2D 0x1>;
        interrupt-names = "mailbox_2";
    };
    hevc_enc {
        compatible = "cnm, HevcEnc";
        dev_name = "HevcEnc";
        status = "okay";
        interrupts = <0x0 0xBB 0x1>;
        interrupt-names = "wave420l_irq";
        #address-cells = <0x2>;
        #size-cells = <0x2>;
        ranges;
        io_reg_base {
            reg = <0x0 0xC8810000 0x0 0x4000>;
        };
    };
    vpu {
        compatible = "amlogic, vpu";
        dev_name = "vpu";
        status = "okay";
        clk_level = <0x7>;
    };
    bt-dev {
        compatible = "amlogic, bt-dev";
        dev_name = "bt-dev";
        status = "disabled";
        gpio_reset = <0x28 0x63 0x0>;
    };
    rtc {
        compatible = "amlogic, aml_vrtc";
        alarm_reg_addr = <0xC81000A8>;
        timer_e_addr = <0xC1109988>;
        init_date = "2015/01/01";
        status = "okay";
    };
    wifi {
        compatible = "amlogic, aml_wifi";
        dev_name = "aml_wifi";
        status = "okay";
        interrupt_pin = <0x28 0x59 0x0>;
        interrupts = <0x0 0x44 0x4>;
        irq_trigger_type = "GPIO_IRQ_HIGH";
        power_on_pin = <0x28 0x58 0x0>;
        dhd_static_buf;
        pinctrl-names = "wifi_32k_pins";
        pinctrl-0 = <0x31>;
    };
    wifi_pwm_conf {
        pwm_channel1 = <0x4>;
        pwm_channel2 = <0xC>;
        pwm_channel1_conf = <0x774D 0x3BA6 0x6>;
        pwm_channel2_conf = <0x7736 0x3B9B 0x9>;
    };
    emmc {
        compatible = "amlogic, aml_sd_emmc";
        dev_name = "aml_newsd.0";
        status = "okay";
        reg = <0x0 0xD0074000 0x0 0x2000>;
        interrupts = <0x0 0xDA 0x1>;
        pinctrl-names = "emmc_clk_cmd_pins", "emmc_all_pins";
        pinctrl-0 = <0x32>;
        pinctrl-1 = <0x33 0x34 0x35>;
        emmc {
            status = "okay";
            pinname = "emmc";
            ocr_avail = <0x200080>;
            caps = "MMC_CAP_8_BIT_DATA", "MMC_CAP_MMC_HIGHSPEED", "MMC_CAP_SD_HIGHSPEED", "MMC_CAP_NONREMOVABLE", "MMC_CAP_1_8V_DDR", "MMC_CAP_HW_RESET", "MMC_CAP_ERASE", "MMC_CAP_CMD23";
            caps2 = "MMC_CAP2_HS200";
            f_min = <0x493E0>;
            f_max = <0x5F5E100>;
            max_req_size = <0x20000>;
            gpio_dat3 = <0x28 0x20 0x0>;
            hw_reset = <0x28 0x26 0x0>;
            card_type = <0x1>;
        };
    };
    sd {
        compatible = "amlogic, aml_sd_emmc";
        dev_name = "aml_newsd.0";
        status = "okay";
        reg = <0x0 0xD0072000 0x0 0x2000>;
        interrupts = <0x0 0xD9 0x1 0x0 0x43 0x1 0x0 0x45 0x1>;
        pinctrl-names = "sd_clk_cmd_pins", "sd_all_pins", "sd_1bit_pins", "sd_clk_cmd_uart_pins", "sd_1bit_uart_pins", "sd_to_ao_uart_pins", "ao_to_sd_uart_pins", "ao_to_sd_jtag_pins", "sd_to_ao_jtag_pins", "sd_clear_all_pin";
        pinctrl-0 = <0x36>;
        pinctrl-1 = <0x37>;
        pinctrl-2 = <0x38>;
        pinctrl-3 = <0x39>;
        pinctrl-4 = <0x3A>;
        pinctrl-5 = <0x3B>;
        pinctrl-6 = <0x3C>;
        pinctrl-7 = <0x3D>;
        pinctrl-8 = <0x3E>;
        pinctrl-9 = <0x3F>;
        sd {
            status = "okay";
            pinname = "sd";
            ocr_avail = <0x200080>;
            caps = "MMC_CAP_4_BIT_DATA", "MMC_CAP_MMC_HIGHSPEED", "MMC_CAP_SD_HIGHSPEED";
            f_min = <0x61A80>;
            f_max = <0x5F5E100>;
            max_req_size = <0x20000>;
            gpio_card5 = <0x28 0x32 0x0>;
            gpio_dat3 = <0x28 0x31 0x0>;
            gpio_card3 = <0x28 0x30 0x0>;
            gpio_card2 = <0x28 0x2F 0x0>;
            gpio_card1 = <0x28 0x2E 0x0>;
            jtag_pin = <0x28 0x2D 0x0>;
            gpio_cd = <0x28 0x33 0x0>;
            irq_in = <0x3>;
            irq_out = <0x5>;
            card_type = <0x5>;
        };
    };
    sdio {
        compatible = "amlogic, aml_sd_emmc";
        dev_name = "aml_newsd.0";
        status = "okay";
        reg = <0x0 0xD0070000 0x0 0x2000>;
        interrupts = <0x0 0xD8 0x4>;
        pinctrl-names = "sdio_clk_cmd_pins", "sdio_all_pins";
        pinctrl-0 = <0x40>;
        pinctrl-1 = <0x41>;
        sdio {
            status = "okay";
            pinname = "sdio";
            ocr_avail = <0x200080>;
            caps = "MMC_CAP_4_BIT_DATA", "MMC_CAP_MMC_HIGHSPEED", "MMC_CAP_SD_HIGHSPEED", "MMC_CAP_NONREMOVABLE", "MMC_CAP_UHS_SDR12", "MMC_CAP_UHS_SDR25", "MMC_CAP_UHS_SDR50", "MMC_CAP_UHS_SDR104", "MMC_PM_KEEP_POWER", "MMC_CAP_SDIO_IRQ";
            f_min = <0x61A80>;
            f_max = <0xBEBC200>;
            vol_switch_delay = <0xA>;
            max_req_size = <0x20000>;
            card_type = <0x3>;
        };
    };
    nand {
        compatible = "amlogic, aml_nand";
        dev_name = "nand";
        status = "disabled";
        reg = <0x0 0xD0074800 0x0 0x200>;
        interrupts = <0x0 0x22 0x1>;
        pinctrl-names = "nand_rb_mod", "nand_norb_mod", "nand_cs_pins_only";
        pinctrl-0 = <0x42 0x43 0x44>;
        pinctrl-1 = <0x42 0x43 0x44>;
        pinctrl-2 = <0x45>;
        device_id = <0x0>;
        plat-names = "nandnormal";
        plat-num = <0x1>;
        plat-part-0 = <0x46>;
        normal {
            enable_pad = "ce0", "ce1", "ce2", "ce3";
            busy_pad = "rb0";
            linux,phandle = <0x46>;
            phandle = <0x46>;
        };
    };
    aml_nftl {
        compatible = "amlogic, nftl";
    };
    unifykey {
        compatible = "amlogic, unifykey";
        status = "ok";
        unifykey-num = <0xE>;
        unifykey-index-0 = <0x47>;
        unifykey-index-1 = <0x48>;
        unifykey-index-2 = <0x49>;
        unifykey-index-3 = <0x4A>;
        unifykey-index-4 = <0x4B>;
        unifykey-index-5 = <0x4C>;
        unifykey-index-6 = <0x4D>;
        unifykey-index-7 = <0x4E>;
        unifykey-index-8 = <0x4F>;
        unifykey-index-9 = <0x50>;
        unifykey-index-10 = <0x51>;
        unifykey-index-11 = <0x52>;
        unifykey-index-12 = <0x53>;
        unifykey-index-13 = <0x54>;
        key_0 {
            key-name = "usid";
            key-device = "normal";
            key-permit = "read", "write", "del";
            linux,phandle = <0x47>;
            phandle = <0x47>;
        };
        key_1 {
            key-name = "mac";
            key-device = "normal";
            key-permit = "read", "write", "del";
            linux,phandle = <0x48>;
            phandle = <0x48>;
        };
        key_2 {
            key-name = "hdcp";
            key-device = "secure";
            key-type = "sha1";
            key-permit = "read", "write", "del";
            linux,phandle = <0x49>;
            phandle = <0x49>;
        };
        key_3 {
            key-name = "secure_boot_set";
            key-device = "efuse";
            key-permit = "write";
            linux,phandle = <0x4A>;
            phandle = <0x4A>;
        };
        key_4 {
            key-name = "mac_bt";
            key-device = "normal";
            key-permit = "read", "write", "del";
            key-type = "mac";
            linux,phandle = <0x4B>;
            phandle = <0x4B>;
        };
        key_5 {
            key-name = "mac_wifi";
            key-device = "normal";
            key-permit = "read", "write", "del";
            key-type = "mac";
            linux,phandle = <0x4C>;
            phandle = <0x4C>;
        };
        key_6 {
            key-name = "hdcp2_tx";
            key-device = "normal";
            key-permit = "read", "write", "del";
            linux,phandle = <0x4D>;
            phandle = <0x4D>;
        };
        key_7 {
            key-name = "hdcp2_rx";
            key-device = "normal";
            key-permit = "read", "write", "del";
            linux,phandle = <0x4E>;
            phandle = <0x4E>;
        };
        key_8 {
            key-name = "widevinekeybox";
            key-device = "secure";
            key-permit = "read", "write", "del";
            linux,phandle = <0x4F>;
            phandle = <0x4F>;
        };
        key_9 {
            key-name = "deviceid";
            key-device = "normal";
            key-permit = "read", "write", "del";
            linux,phandle = <0x50>;
            phandle = <0x50>;
        };
        key_10 {
            key-name = "hdcp22_fw_private";
            key-device = "secure";
            key-permit = "read", "write", "del";
            linux,phandle = <0x51>;
            phandle = <0x51>;
        };
        key_11 {
            key-name = "PlayReadykeybox25";
            key-device = "secure";
            key-permit = "read", "write", "del";
            linux,phandle = <0x52>;
            phandle = <0x52>;
        };
        key_12 {
            key-name = "prpubkeybox";
            key-device = "secure";
            key-permit = "read", "write", "del";
            linux,phandle = <0x53>;
            phandle = <0x53>;
        };
        key_13 {
            key-name = "prprivkeybox";
            key-device = "secure";
            key-permit = "read", "write", "del";
            linux,phandle = <0x54>;
            phandle = <0x54>;
        };
    };
    amhdmitx {
        compatible = "amlogic, amhdmitx";
        dev_name = "amhdmitx";
        status = "okay";
        pinctrl-names = "hdmitx_hpd", "hdmitx_ddc";
        pinctrl-0 = <0x55>;
        pinctrl-1 = <0x56>;
        interrupts = <0x0 0x39 0x1>;
        interrupt-names = "hdmitx_hpd";
        clocks = <0x7 0xB 0x7 0xC 0x7 0xD 0x7 0xE 0x7 0xF 0x7 0x16>;
        clock-names = "hdmitx_clk_sys", "hdmitx_clk_encp", "hdmitx_clk_enci", "hdmitx_clk_pixel", "hdmitx_clk_phy", "hdmitx_clk_vid";
        gpio_i2c_en = <0x1>;
        #address-cells = <0x2>;
        #size-cells = <0x2>;
        ranges;
    };
    aocec {
        compatible = "amlogic, amlogic-aocec";
        device_name = "aocec";
        status = "okay";
        vendor_name = "Amlogic";
        vendor_id = <0x0>;
        product_desc = "GXBB Mbox";
        cec_osd_string = "MBox";
        port_num = <0x1>;
        arc_port_mask = <0x0>;
        interrupts = <0x0 0xC7 0x1>;
        interrupt-names = "hdmi_aocec";
        pinctrl-names = "hdmitx_aocec";
        pinctrl-0 = <0x57>;
        reg = <0x0 0xC810023C 0x0 0x4 0x0 0xC8100000 0x0 0x200>;
    };
    tvout {
        compatible = "amlogic, tvout";
        dev_name = "tvout";
        status = "okay";
    };
    i2c_gpio {
        compatible = "i2c-gpio";
        status = "okay";
        dev_name = "i2c-gpio";
        i2c-gpio,delay-us = <0xA>;
        gpios = <0x28 0x11 0x0 0x28 0x12 0x0>;
        #address-cells = <0x2>;
        #size-cells = <0x2>;
        i2c-gpio,timeout-ms = <0xA>;
        i2c_gpio_edid {
            compatible = "i2c-gpio-edid";
            reg = <0x50 0x0 0x0 0x0>;
        };
    };
    serial@c81004c0 {
        compatible = "amlogic, meson-uart";
        reg = <0x0 0xC81004C0 0x0 0x18>;
        interrupts = <0x0 0xC1 0x1>;
        status = "okay";
        clocks = <0x7 0x2>;
        clock-names = "clk_uart";
        xtal_tick_en = <0x1>;
        fifosize = <0x40>;
        pinctrl-names = "default";
        support-sysrq = <0x0>;
    };
    serial@c11084c0 {
        compatible = "amlogic, meson-uart";
        reg = <0x0 0xC11084C0 0x0 0x18>;
        interrupts = <0x0 0x1A 0x1>;
        status = "okay";
        clocks = <0x7 0x2>;
        clock-names = "clk_uart";
        fifosize = <0x80>;
        pinctrl-names = "default";
        pinctrl-0 = <0x58>;
        resets = <0x7 0xD>;
    };
    serial@c11084dc {
        compatible = "amlogic, meson-uart";
        reg = <0x0 0xC11084DC 0x0 0x18>;
        interrupts = <0x0 0x4B 0x1>;
        status = "disable";
        clocks = <0x7 0x2>;
        clock-names = "clk_uart";
        fifosize = <0x40>;
        pinctrl-names = "default";
        pinctrl-0 = <0x59>;
        resets = <0x7 0x30>;
    };
    serial@c1108700 {
        compatible = "amlogic, meson-uart";
        reg = <0x0 0xC1108700 0x0 0x18>;
        interrupts = <0x0 0x5D 0x1>;
        status = "disable";
        clocks = <0x7 0x2>;
        clock-names = "clk_uart";
        fifosize = <0x40>;
        pinctrl-names = "default";
        pinctrl-0 = <0x5A>;
        resets = <0x7 0x4F>;
    };
    serial@c81004e0 {
        compatible = "amlogic, meson-uart";
        reg = <0x0 0xC81004E0 0x0 0x18>;
        interrupts = <0x0 0xC5 0x1>;
        status = "disable";
        clocks = <0x7 0x2>;
        clock-names = "clk_uart";
        fifosize = <0x40>;
        pinctrl-names = "default";
        pinctrl-0 = <0x5B>;
    };
    canvas {
        compatible = "amlogic, meson, canvas";
        dev_name = "amlogic-canvas";
        status = "okay";
        reg = <0x0 0xC8838000 0x0 0x400>;
    };
    rdma {
        compatible = "amlogic, meson, rdma";
        dev_name = "amlogic-rdma";
        status = "okay";
        interrupts = <0x0 0x59 0x1>;
        interrupt-names = "rdma";
    };
    dwc3@c9000000 {
        compatible = "synopsys, dwc3";
        reg = <0x0 0xC9000000 0x0 0x100000>;
        interrupts = <0x0 0x1E 0x4>;
        usb-phy = <0x5C 0x5D>;
        cpu-type = "gxl";
        clock-src = "usb3.0";
    };
    usb2phy@d0078000 {
        compatible = "amlogic, amlogic-new-usb2";
        portnum = <0x2>;
        reg = <0x0 0xD0078000 0x0 0x80>;
        linux,phandle = <0x5C>;
        phandle = <0x5C>;
    };
    usb3phy@d0078080 {
        compatible = "amlogic, amlogic-new-usb3";
        portnum = <0x0>;
        reg = <0x0 0xD0078080 0x0 0x20>;
        linux,phandle = <0x5D>;
        phandle = <0x5D>;
    };
    dwc2_a {
        compatible = "amlogic,dwc2";
        device_name = "dwc2_a";
        reg = <0x0 0xC9100000 0x0 0x40000>;
        status = "okay";
        interrupts = <0x0 0x1F 0x4>;
        pl-periph-id = <0x0>;
        clock-src = "usb0";
        port-id = <0x0>;
        port-type = <0x2>;
        port-speed = <0x0>;
        port-config = <0x0>;
        port-dma = <0x0>;
        port-id-mode = <0x0>;
        usb-fifo = <0x2D8>;
        cpu-type = "gxl";
        controller-type = <0x1>;
        phy-reg = <0xD0078000>;
        phy-reg-size = <0xA0>;
        resets = <0x7 0x3A 0x7 0x48 0x7 0x36>;
        reset-names = "usb_general", "usb1", "usb1_to_ddr";
    };
    I2S {
        #sound-dai-cells = <0x0>;
        resets = <0x7 0x26 0x7 0x12 0x7 0x28 0x7 0x29 0x7 0x2A 0x7 0x2B 0x7 0x2C 0x7 0x2D 0x7 0x2F 0x7 0x8E 0x7 0x22>;
        reset-names = "top_glue", "aud_buf", "i2s_out", "amclk_measure", "aififo2", "aud_mixer", "mixer_reg", "adc", "top_level", "aoclk", "aud_in";
        clocks = <0x7 0x21 0x7 0x22>;
        clock-names = "mpll2", "mclk";
        compatible = "amlogic, aml-i2s-dai";
        linux,phandle = <0x69>;
        phandle = <0x69>;
    };
    SPDIF {
        #sound-dai-cells = <0x0>;
        compatible = "amlogic, aml-spdif-dai";
        resets = <0x7 0x27 0x7 0x90>;
        reset-names = "iec958", "iec958_amclk";
        clocks = <0x7 0x20 0x7 0x24 0x7 0x22 0x7 0x25 0x7 0xA>;
        clock-names = "mpll1", "i958", "mclk", "spdif", "clk_81";
        linux,phandle = <0x6A>;
        phandle = <0x6A>;
    };
    PCM {
        #sound-dai-cells = <0x0>;
        compatible = "amlogic, aml-pcm-dai";
        pinctrl-names = "aml_audio_btpcm";
        pinctrl-0 = <0x5E>;
        clocks = <0x7 0x1F 0x7 0x2A 0x7 0x2B>;
        clock-names = "mpll0", "pcm_mclk", "pcm_sclk";
        pcm_mode = <0x1>;
        linux,phandle = <0x6B>;
        phandle = <0x6B>;
    };
    i2s_platform {
        compatible = "amlogic, aml-i2s";
        interrupts = <0x0 0x1D 0x1>;
        linux,phandle = <0x67>;
        phandle = <0x67>;
    };
    pcm_platform {
        compatible = "amlogic, aml-pcm";
        linux,phandle = <0x68>;
        phandle = <0x68>;
    };
    spdif_codec {
        #sound-dai-cells = <0x0>;
        compatible = "amlogic, aml-spdif-codec";
        pinctrl-names = "aml_audio_spdif";
        pinctrl-0 = <0x5F>;
        linux,phandle = <0x6D>;
        phandle = <0x6D>;
    };
    pcm_codec {
        #sound-dai-cells = <0x0>;
        compatible = "amlogic, pcm2BT-codec";
        linux,phandle = <0x6E>;
        phandle = <0x6E>;
    };
    dummy {
        #sound-dai-cells = <0x0>;
        compatible = "amlogic, aml_dummy_codec";
        status = "disable";
    };
    t9015 {
        #sound-dai-cells = <0x0>;
        compatible = "amlogic, aml_codec_T9015";
        reg = <0x0 0xC8832000 0x0 0x14>;
        status = "okay";
        linux,phandle = <0x6C>;
        phandle = <0x6C>;
    };
    aml_m8_snd {
        compatible = "aml, aml_snd_m8";
        status = "okay";
        aml-sound-card,format = "i2s";
        aml_sound_card,name = "AML-M8AUDIO";
        aml,audio-routing = "Ext Spk", "LOUTL", "Ext Spk", "LOUTR";
        mute_gpio-gpios = <0x28 0x15 0x0>;
        mute_inv;
        sleep_time = <0x12C>;
        hp_disable;
        hp_paraments = <0x320 0x12C 0x0 0x5 0x1>;
        pinctrl-names = "aml_snd_m8";
        pinctrl-0 = <0x60>;
        cpu_list = <0x61 0x62 0x63>;
        codec_list = <0x64 0x65 0x66>;
        plat_list = <0x67 0x67 0x68>;
        cpudai0 {
            sound-dai = <0x69>;
            linux,phandle = <0x61>;
            phandle = <0x61>;
        };
        cpudai1 {
            sound-dai = <0x6A>;
            linux,phandle = <0x62>;
            phandle = <0x62>;
        };
        cpudai2 {
            sound-dai = <0x6B>;
            linux,phandle = <0x63>;
            phandle = <0x63>;
        };
        codec0 {
            sound-dai = <0x6C>;
            linux,phandle = <0x64>;
            phandle = <0x64>;
        };
        codec1 {
            sound-dai = <0x6D>;
            linux,phandle = <0x65>;
            phandle = <0x65>;
        };
        codec2 {
            sound-dai = <0x6E>;
            linux,phandle = <0x66>;
            phandle = <0x66>;
        };
    };
    gpio_keypad {
        compatible = "amlogic, gpio_keypad";
        status = "okay";
        scan_period = <0x14>;
        key_num = <0x2>;
        key_name = "power1", "power2";
        key_code = <0x74 0x74>;
        key_pin = <0x6F 0x2 0x0 0x6F 0x6 0x0>;
        irq_keyup = <0x6>;
        irq_keydown = <0x7>;
    };
    aml-sensor@0 {
        compatible = "amlogic, aml-thermal";
        device_name = "thermal";
        #thermal-sensor-cells = <0x1>;
        linux,phandle = <0x70>;
        phandle = <0x70>;
        cooling_devices {
            cpufreq_cool_cluster0 {
                min_state = <0xF4240>;
                dyn_coeff = <0x8C>;
                cluster_id = <0x0>;
                node_name = "cpus";
                device_type = "cpufreq";
            };
            cpucore_cool_cluster0 {
                min_state = <0x1>;
                dyn_coeff = <0x0>;
                cluster_id = <0x0>;
                node_name = "cpu_core_cluster0";
                device_type = "cpucore";
            };
            gpufreq_cool {
                min_state = <0x190>;
                dyn_coeff = <0x1B5>;
                cluster_id = <0x0>;
                node_name = "mali";
                device_type = "gpufreq";
            };
            gpucore_cool {
                min_state = <0x1>;
                dyn_coeff = <0x0>;
                cluster_id = <0x0>;
                node_name = "thermal_gpu_cores";
                device_type = "gpucore";
            };
        };
        cpu_core_cluster0 {
            #cooling-cells = <0x2>;
            linux,phandle = <0x73>;
            phandle = <0x73>;
        };
        thermal_gpu_cores {
            #cooling-cells = <0x2>;
            linux,phandle = <0x75>;
            phandle = <0x75>;
        };
    };
    thermal-zones {
        soc_thermal {
            polling-delay = <0x3E8>;
            polling-delay-passive = <0x64>;
            sustainable-power = <0x866>;
            thermal-sensors = <0x70 0x3>;
            trips {
                trip-point@0 {
                    temperature = <0x11170>;
                    hysteresis = <0x3E8>;
                    type = "passive";
                };
                trip-point@1 {
                    temperature = <0x13880>;
                    hysteresis = <0x3E8>;
                    type = "passive";
                    linux,phandle = <0x71>;
                    phandle = <0x71>;
                };
                trip-point@2 {
                    temperature = <0x14C08>;
                    hysteresis = <0x1388>;
                    type = "hot";
                };
                trip-point@3 {
                    temperature = <0x3F7A0>;
                    hysteresis = <0x3E8>;
                    type = "critical";
                };
            };
            cooling-maps {
                cpufreq_cooling_map {
                    trip = <0x71>;
                    cooling-device = <0x72 0x0 0x4>;
                    contribution = <0x400>;
                };
                cpucore_cooling_map {
                    trip = <0x71>;
                    cooling-device = <0x73 0x0 0x3>;
                    contribution = <0x400>;
                };
                gpufreq_cooling_map {
                    trip = <0x71>;
                    cooling-device = <0x74 0x0 0x4>;
                    contribution = <0x400>;
                };
                gpucore_cooling_map {
                    trip = <0x71>;
                    cooling-device = <0x75 0x0 0x2>;
                    contribution = <0x400>;
                };
            };
        };
    };
};
